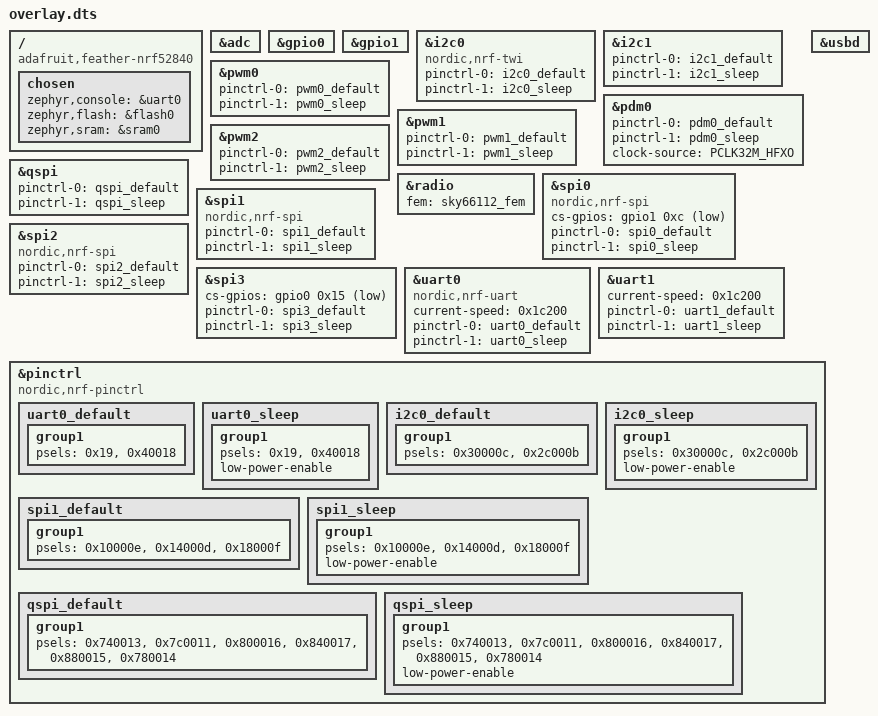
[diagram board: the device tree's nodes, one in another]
/ {
	compatible = "adafruit,feather-nrf52840";
	chosen {
		zephyr,console = &uart0;
		zephyr,flash = &flash0;
		zephyr,sram = &sram0;
	};
};
&adc{
	status = "okay";
};
&gpio0{
	status = "okay";
};
&gpio1{
	status = "okay";
};
&i2c0{
	compatible = "nordic,nrf-twi";
	status = "okay";
	pinctrl-0 = < &i2c0_default >;
	pinctrl-1 = < &i2c0_sleep >;
	pinctrl-names = "default", "sleep";
};
&i2c1{
	status = "okay";
	pinctrl-0 = < &i2c1_default >;
	pinctrl-1 = < &i2c1_sleep >;
	pinctrl-names = "default", "sleep";
};
&pdm0{
	status = "okay";
	pinctrl-0 = < &pdm0_default >;
	pinctrl-1 = < &pdm0_sleep >;
	pinctrl-names = "default", "sleep";
	clock-source = "PCLK32M_HFXO";
};
&pwm0{
	status = "okay";
	pinctrl-0 = < &pwm0_default >;
	pinctrl-1 = < &pwm0_sleep >;
	pinctrl-names = "default", "sleep";
};
&pwm1{
	status = "okay";
	pinctrl-0 = < &pwm1_default >;
	pinctrl-1 = < &pwm1_sleep >;
	pinctrl-names = "default", "sleep";
};
&pwm2{
	pinctrl-0 = < &pwm2_default >;
	pinctrl-1 = < &pwm2_sleep >;
	pinctrl-names = "default", "sleep";
};
&qspi{
	status = "okay";
	pinctrl-0 = < &qspi_default >;
	pinctrl-1 = < &qspi_sleep >;
	pinctrl-names = "default", "sleep";
};
&radio{
	fem = < &sky66112_fem >;
};
&spi0{
	compatible = "nordic,nrf-spi";
	cs-gpios = < &gpio1 0xc 0x1 >;
	pinctrl-0 = < &spi0_default >;
	pinctrl-1 = < &spi0_sleep >;
	pinctrl-names = "default", "sleep";
};
&spi1{
	compatible = "nordic,nrf-spi";
	status = "okay";
	pinctrl-0 = < &spi1_default >;
	pinctrl-1 = < &spi1_sleep >;
	pinctrl-names = "default", "sleep";
};
&spi2{
	compatible = "nordic,nrf-spi";
	status = "okay";
	pinctrl-0 = < &spi2_default >;
	pinctrl-1 = < &spi2_sleep >;
	pinctrl-names = "default", "sleep";
};
&spi3{
	status = "okay";
	cs-gpios = < &gpio0 0x15 0x1 >;
	pinctrl-0 = < &spi3_default >;
	pinctrl-1 = < &spi3_sleep >;
	pinctrl-names = "default", "sleep";
};
&uart0{
	compatible = "nordic,nrf-uart";
	status = "okay";
	current-speed = < 0x1c200 >;
	pinctrl-0 = < &uart0_default >;
	pinctrl-1 = < &uart0_sleep >;
	pinctrl-names = "default", "sleep";
};
&uart1{
	status = "okay";
	current-speed = < 0x1c200 >;
	pinctrl-0 = < &uart1_default >;
	pinctrl-1 = < &uart1_sleep >;
	pinctrl-names = "default", "sleep";
};
&usbd{
	status = "okay";
};
&pinctrl{
	compatible = "nordic,nrf-pinctrl";
	uart0_default: uart0_default {
		group1 {
			psels = < 0x19 >, < 0x40018 >;
		};
	};
	uart0_sleep: uart0_sleep {
		group1 {
			psels = < 0x19 >, < 0x40018 >;
			low-power-enable;
		};
	};
	i2c0_default: i2c0_default {
		group1 {
			psels = < 0x30000c >, < 0x2c000b >;
		};
	};
	i2c0_sleep: i2c0_sleep {
		group1 {
			psels = < 0x30000c >, < 0x2c000b >;
			low-power-enable;
		};
	};
	spi1_default: spi1_default {
		group1 {
			psels = < 0x10000e >, < 0x14000d >, < 0x18000f >;
		};
	};
	spi1_sleep: spi1_sleep {
		group1 {
			psels = < 0x10000e >, < 0x14000d >, < 0x18000f >;
			low-power-enable;
		};
	};
	qspi_default: qspi_default {
		group1 {
			psels = < 0x740013 >, < 0x7c0011 >, < 0x800016 >, < 0x840017 >, < 0x880015 >, < 0x780014 >;
		};
	};
	qspi_sleep: qspi_sleep {
		group1 {
			psels = < 0x740013 >, < 0x7c0011 >, < 0x800016 >, < 0x840017 >, < 0x880015 >, < 0x780014 >;
			low-power-enable;
		};
	};
};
